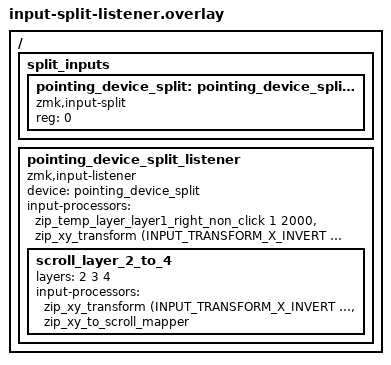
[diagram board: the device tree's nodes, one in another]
#include <input/processors.dtsi>

/ {
    split_inputs {
        #address-cells = <1>;
        #size-cells = <0>;

        pointing_device_split: pointing_device_split@0 {
            compatible = "zmk,input-split";
            reg = <0>;
        };
    };

    pointing_device_split_listener: pointing_device_split_listener {
        compatible = "zmk,input-listener";
        device = <&pointing_device_split>;
        status = "okay";
        input-processors = <&zip_temp_layer_layer1_right_non_click 1 2000 &zip_xy_transform (INPUT_TRANSFORM_X_INVERT | INPUT_TRANSFORM_Y_INVERT)>;

        scroll_layer_2_to_4 {
            layers = <2 3 4>;
            input-processors = <&zip_xy_transform (INPUT_TRANSFORM_X_INVERT | INPUT_TRANSFORM_Y_INVERT) &zip_xy_to_scroll_mapper>;
        };
     };
};
